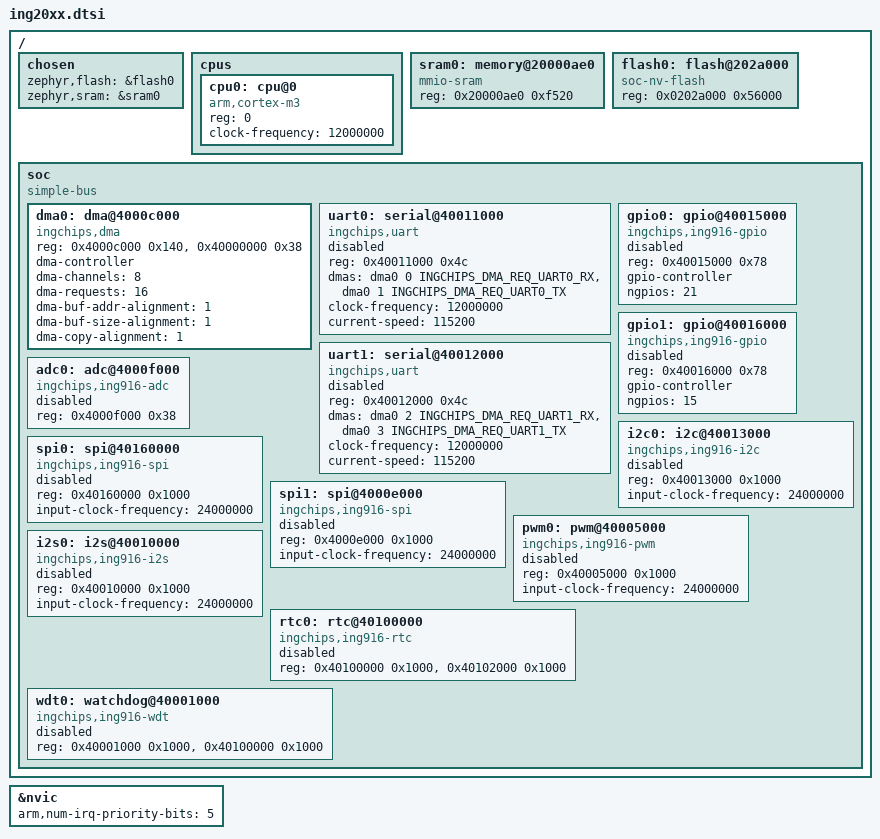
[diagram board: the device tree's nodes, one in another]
/* SPDX-License-Identifier: Apache-2.0 */
#include <arm/armv7-m.dtsi>
#include <zephyr/dt-bindings/dma/ingchips-dma.h>

/ {
	chosen { zephyr,flash = &flash0; zephyr,sram = &sram0; };
	cpus {
		#address-cells = <1>; #size-cells = <0>;
		cpu0: cpu@0 {
			compatible = "arm,cortex-m3"; device_type = "cpu"; reg = <0>;
			clock-frequency = <12000000>;
		};
	};
	sram0: memory@20000ae0 { compatible = "mmio-sram"; reg = <0x20000ae0 0xf520>; };
	flash0: flash@202a000 { compatible = "soc-nv-flash"; reg = <0x0202a000 0x56000>; };
	soc {
		compatible = "simple-bus";
		dma0: dma@4000c000 {
			compatible = "ingchips,dma";
			reg = <0x4000c000 0x140>, <0x40000000 0x38>;
			reg-names = "dma", "sysctrl";
			dma-controller;
			#dma-cells = <2>;
			dma-channels = <8>;
			dma-requests = <16>;
			dma-buf-addr-alignment = <1>;
			dma-buf-size-alignment = <1>;
			dma-copy-alignment = <1>;
			status = "okay";
		};
		uart0: serial@40011000 {
			compatible = "ingchips,uart"; reg = <0x40011000 0x4c>;
			dmas = <&dma0 0 INGCHIPS_DMA_REQ_UART0_RX>,
			       <&dma0 1 INGCHIPS_DMA_REQ_UART0_TX>;
			dma-names = "rx", "tx";
			clock-frequency = <12000000>; current-speed = <115200>; status = "disabled";
		};
		uart1: serial@40012000 {
			compatible = "ingchips,uart"; reg = <0x40012000 0x4c>;
			dmas = <&dma0 2 INGCHIPS_DMA_REQ_UART1_RX>,
			       <&dma0 3 INGCHIPS_DMA_REQ_UART1_TX>;
			dma-names = "rx", "tx";
			clock-frequency = <12000000>; current-speed = <115200>; status = "disabled";
		};
		gpio0: gpio@40015000 {
			compatible = "ingchips,ing916-gpio"; reg = <0x40015000 0x78>;
			gpio-controller; #gpio-cells = <2>; ngpios = <21>; status = "disabled";
		};
		gpio1: gpio@40016000 {
			compatible = "ingchips,ing916-gpio"; reg = <0x40016000 0x78>;
			gpio-controller; #gpio-cells = <2>; ngpios = <15>; status = "disabled";
		};
		adc0: adc@4000f000 {
			compatible = "ingchips,ing916-adc";
			reg = <0x4000f000 0x38>;
			#io-channel-cells = <1>;
			status = "disabled";
		};
		i2c0: i2c@40013000 {
			compatible = "ingchips,ing916-i2c";
			reg = <0x40013000 0x1000>;
			input-clock-frequency = <24000000>;
			#address-cells = <1>; #size-cells = <0>;
			status = "disabled";
		};
		spi0: spi@40160000 {
			compatible = "ingchips,ing916-spi";
			reg = <0x40160000 0x1000>;
			input-clock-frequency = <24000000>;
			#address-cells = <1>; #size-cells = <0>;
			status = "disabled";
		};
		spi1: spi@4000e000 {
			compatible = "ingchips,ing916-spi";
			reg = <0x4000e000 0x1000>;
			input-clock-frequency = <24000000>;
			#address-cells = <1>; #size-cells = <0>;
			status = "disabled";
		};
		pwm0: pwm@40005000 {
			compatible = "ingchips,ing916-pwm";
			reg = <0x40005000 0x1000>;
			input-clock-frequency = <24000000>;
			#pwm-cells = <3>;
			status = "disabled";
		};
		i2s0: i2s@40010000 {
			compatible = "ingchips,ing916-i2s";
			reg = <0x40010000 0x1000>;
			input-clock-frequency = <24000000>;
			status = "disabled";
		};
		rtc0: rtc@40100000 {
			compatible = "ingchips,ing916-rtc";
			reg = <0x40100000 0x1000>, <0x40102000 0x1000>;
			reg-names = "counter", "control";
			status = "disabled";
		};
		wdt0: watchdog@40001000 {
			compatible = "ingchips,ing916-wdt";
			reg = <0x40001000 0x1000>, <0x40100000 0x1000>;
			reg-names = "wdt", "aon";
			status = "disabled";
		};
	};
};
&nvic { arm,num-irq-priority-bits = <5>; };
